# ATUC64D3 device description
Architecture: AVR32_UC3; Family: AVR UC3
Registers are 32-bit, read-write, reset 0x0 unless marked. A register's access mark holds for its fields unless they carry their own. Offsets are from the block's base; [hi:lo] are bit positions; lines under a group give offsets from that group; {n}, {i} and the like mark numbered series; 'fields as' and 'values as' point back to an identical list.

## PM — Power Manager
Instances: PM 0xffff1400
Parameters: PM_SMODE_DEEPSTOP=4, PM_SMODE_FROZEN=1, PM_SMODE_IDLE=0, PM_SMODE_SHUTDOWN=6, PM_SMODE_STANDBY=2, PM_SMODE_STATIC=5, PM_SMODE_STOP=3
0x00 MCCTRL — Main Clock Control
  [2:0] MCSEL — Main Clock Select
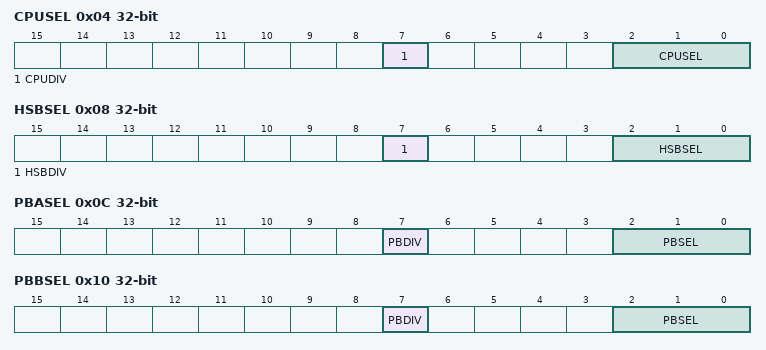
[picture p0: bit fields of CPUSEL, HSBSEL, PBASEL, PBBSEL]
0x04 CPUSEL — CPU Clock Select
  [7] CPUDIV — CPU Division Select
  [2:0] CPUSEL — CPU Clock Select
0x08 HSBSEL — HSB Clock Select
  [7] HSBDIV — HSB Division Select
  [2:0] HSBSEL — HSB Clock Select
0x0C PBASEL — PBA Clock Select
  [7] PBDIV — PB Division Select
  [2:0] PBSEL — PB Clock Select
0x10 PBBSEL — PBB Clock Select
  [7] PBDIV — PB Division Select
  [2:0] PBSEL — PB Clock Select
0x20 CPUMASK reset not defined
0x24 HSBMASK reset not defined
0x28 PBAMASK reset not defined
0x2C PBBMASK reset not defined
0x40 PBADIVMASK reset not defined — PBA Divided Mask
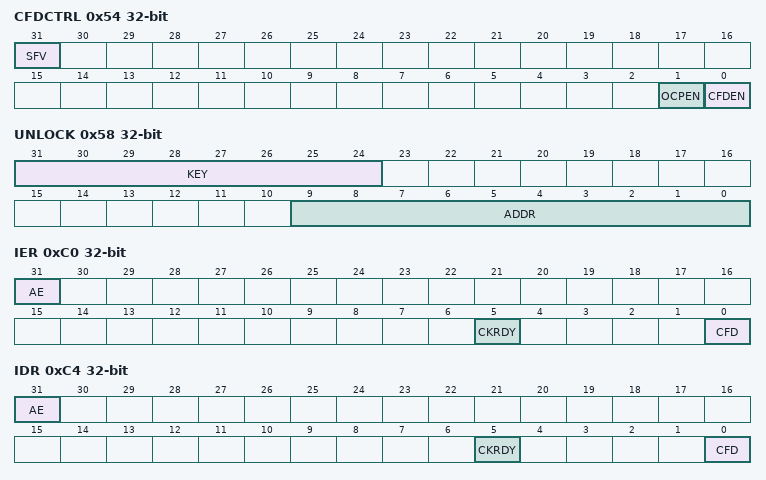
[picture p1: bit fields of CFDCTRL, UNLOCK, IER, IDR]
0x54 CFDCTRL — Clock Failure Detector Control
  [31] SFV — Stor final value
  [1] OCPEN — Over Clock Protection Enable
  [0] CFDEN — Clock Failure Detection Enable
0x58 UNLOCK wo
  [31:24] KEY — Unlock Key
  [9:0] ADDR — Unlock Address
0xC0 IER wo — PM Interrupt Enable Register
  [31] AE — Access Error
  [5] CKRDY — Clock Ready
  [0] CFD — Clock Failure Detected
0xC4 IDR wo — PM Interrupt Disable Register
  fields as IER
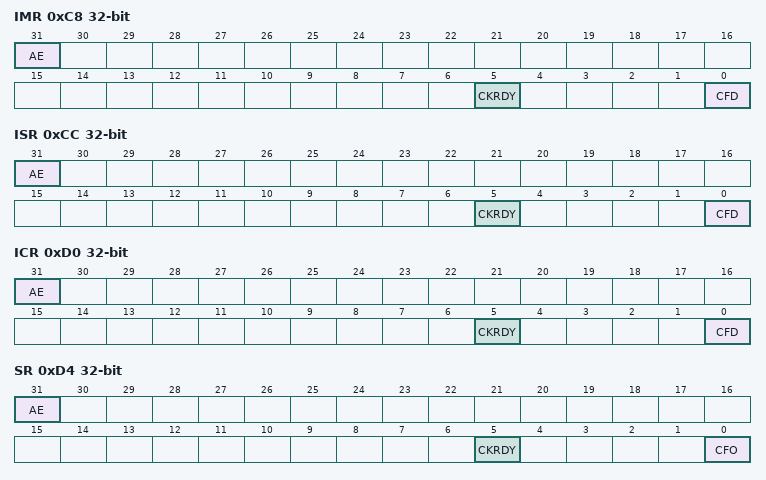
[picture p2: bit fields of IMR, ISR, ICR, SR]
0xC8 IMR ro — PM Interrupt Mask Register
  fields as IER
0xCC ISR ro — PM Interrupt Status Register
  fields as IER
0xD0 ICR wo — PM Interrupt Clear Register
  fields as IER
0xD4 SR ro — Status Register
  [31] AE — Access Error
  [5] CKRDY — Clock Ready
  [0] CFO — Clock Failure Detected
0x160 PPCR — Peripheral Power Control Register
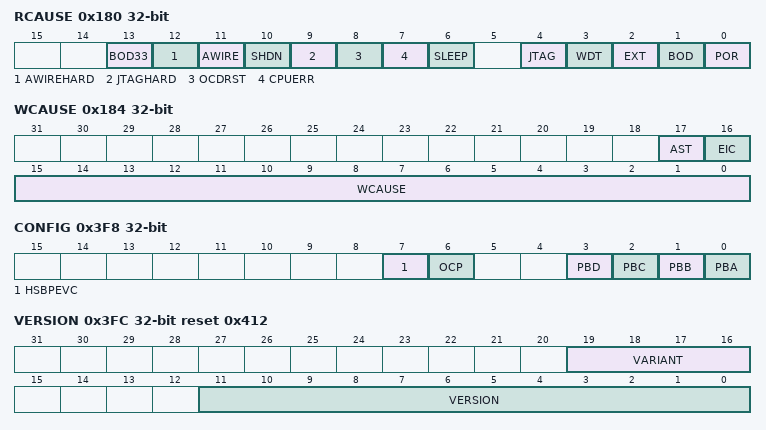
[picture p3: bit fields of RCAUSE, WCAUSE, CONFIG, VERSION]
0x180 RCAUSE ro — Reset Cause Register
  [13] BOD33 — Brown-out 3.3V Reset
  [12] AWIREHARD — AWire Hard Reset
  [11] AWIRE
  [10] SHDN — Shutdown Controller
  [9] JTAGHARD — JTAG Hard Reset
  [8] OCDRST — OCD Reset
  [7] CPUERR — CPU Error
  [6] SLEEP
  [4] JTAG — JTAG reset
  [3] WDT — Watchdog Reset
  [2] EXT — External Reset Pin
  [1] BOD — Brown-out Reset
  [0] POR — Power-on Reset
0x184 WCAUSE ro — Wake Cause Register
  [17] AST — Asynchronous Timer
  [16] EIC — External Interrupt Controller
  [15:0] WCAUSE — Wake Cause
0x188 AWEN — Asynchronous Wake Enable
  [31:0] AWEN — Aynchronous Wake Enabled
0x3F8 CONFIG ro reset not defined — Configureation Register
  [7] HSBPEVC — HSB PEVC Clock Implemented
  [6] OCP — Over Clock Protection Implemented
  [3] PBD — PBD Implemented
  [2] PBC — PBC Implemented
  [1] PBB — PBB Implemented
  [0] PBA — PBA Implemented
0x3FC VERSION ro reset 0x412
  [19:16] VARIANT — Variant number
  [11:0] VERSION — Version number

## PWMA — Pulse Width Modulation Controller
Instances: PWMA 0xffff4800
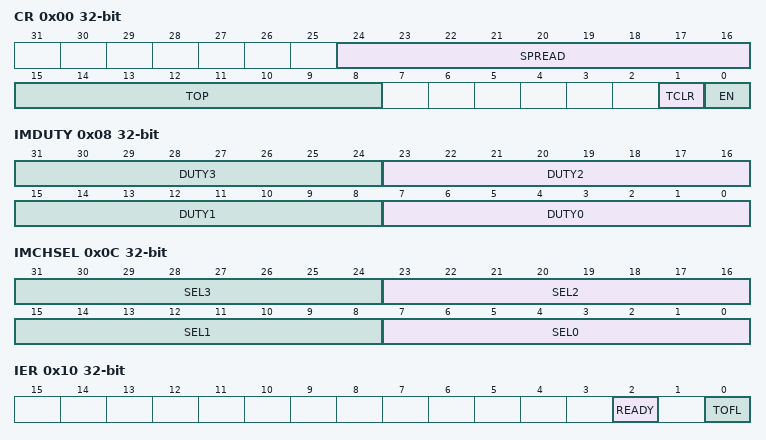
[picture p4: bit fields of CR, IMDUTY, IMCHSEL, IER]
0x00 CR — Control Register
  [24:16] SPREAD — Spread Spectrum Counter Value
  [15:8] TOP — Timebase Counter Top Value
  [1] TCLR — Timebase Clear
  [0] EN — Module enable
0x04 ISDUTY wo — Interlinked Single Value Duty Register
  [11:0] DUTY — Duty Cycle Value
0x08 IMDUTY wo — Interlinked Multiple Value Duty Register
  [8n+7:8n] DUTY{n} (n=0..3) — Duty cycle
0x0C IMCHSEL wo — Interlinked Multiple Value Channel Select
  [8n+7:8n] SEL{n} (n=0..3) — Channel Select {n}
0x10 IER wo — Interrupt Enable Register
  [2] READY — Interface Ready
  [0] TOFL — Timebase Overflow
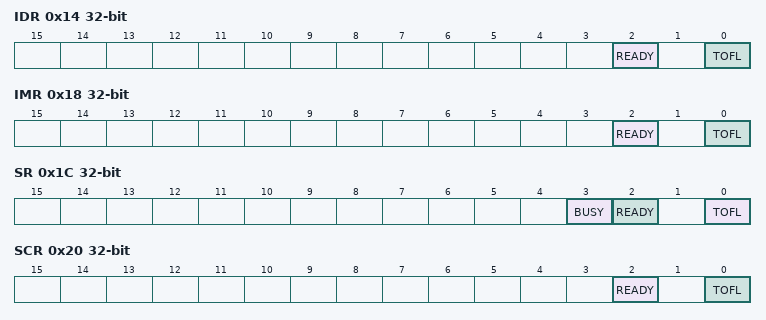
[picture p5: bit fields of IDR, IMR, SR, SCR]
0x14 IDR wo — Interrupt Disable Register
  [2] READY — Interface Ready
  [0] TOFL — Timebase Overflow
0x18 IMR ro — Interrupt Mask Register
  [2] READY — Interface Ready
  [0] TOFL — Timebase Overflow
0x1C SR ro — Status Register
  [3] BUSY — Interface Busy
  [2] READY — Interface Ready
  [0] TOFL — Timebase Overflow
0x20 SCR wo — Status Clear Register
  [2] READY — Interface Ready
  [0] TOFL — Timebase Overflow
0x24 PARAMETER ro reset 0x24
  [7:0] CHANNELS — Channels implemented
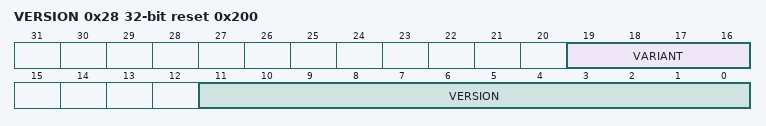
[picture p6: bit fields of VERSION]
0x28 VERSION ro reset 0x200
  [19:16] VARIANT — Variant number
  [11:0] VERSION — Version number
0x2C TVR — Top Value Register
  [11:0] TOP — Timebase Counter Top Value
{0x30+0x10*i} CHGROUP[{i}] (i=0..4) group
  0x00 ISCHSE wo — Interlinked Single Value Channel
    [31:0] SET — Single Value Channel Set
  0x04 CHER — Channel Event Response Register
    [31:0] CHER — Channel Event Response
  0x08 CHEE — Channel Event Enable Register
    [31:0] CHEE — Channel Event Enable
  0x0C CW — Composite Waveform Generator
    [31:0] XOR — Pair Waveform XORed
{0x80+4i} DUTY{i} wo (i=0..3) — Duty Value Register {i}
  [11:0] DUTY — Duty Cycle Value
